VERSION ""

NS_ :

BS_:

BU_: Engine Transmission Brakes Instrument DiagTool

VAL_TABLE_ VT_FMI
    0 "Data Valid Above Normal Range"
    1 "Data Valid Below Normal Range"
    2 "Data Erratic"
    3 "Voltage Above Normal"
    4 "Voltage Below Normal"
    5 "Current Below Normal / Open Circuit"
    6 "Current Above Normal / Ground Fault"
    7 "Mechanical Not Responding"
    8 "Abnormal Frequency"
    9 "Abnormal Update Rate"
    10 "Abnormal Rate of Change"
    11 "Root Cause Unknown"
    12 "Bad Device"
    13 "Out of Calibration"
    14 "Special Instructions"
    15 "Reserved"
    31 "Not Available" ;

VAL_TABLE_ VT_GearStatus
    0 "Neutral"
    126 "Park"
    125 "Reverse"
    251 "Error"
    252 "Not Available" ;

VAL_TABLE_ VT_OnOff
    0 "Off"
    1 "On"
    2 "Error"
    3 "Not Available" ;

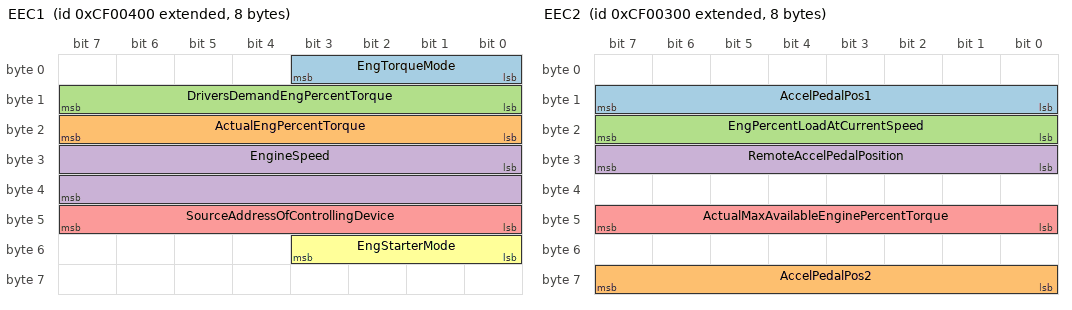
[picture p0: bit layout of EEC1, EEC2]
BO_ 2364539904 EEC1: 8 Engine
 SG_ EngTorqueMode : 0|4@1+ (1,0) [0|15] "" Instrument
 SG_ ActualEngPercentTorque : 16|8@1+ (1,-125) [-125|125] "%" Instrument
 SG_ DriversDemandEngPercentTorque : 8|8@1+ (1,-125) [-125|125] "%" Instrument
 SG_ EngineSpeed : 24|16@1+ (0.125,0) [0|8031.875] "rpm" Instrument,Transmission
 SG_ SourceAddressOfControllingDevice : 40|8@1+ (1,0) [0|255] "" DiagTool
 SG_ EngStarterMode : 48|4@1+ (1,0) [0|15] "" Instrument

BO_ 2364539648 EEC2: 8 Engine
 SG_ AccelPedalPos1 : 8|8@1+ (0.4,0) [0|102] "%" Instrument
 SG_ AccelPedalPos2 : 56|8@1+ (0.4,0) [0|102] "%" Instrument
 SG_ EngPercentLoadAtCurrentSpeed : 16|8@1+ (1,0) [0|100] "%" Instrument
 SG_ RemoteAccelPedalPosition : 24|8@1+ (0.4,0) [0|102] "%" Instrument
 SG_ ActualMaxAvailableEnginePercentTorque : 40|8@1+ (0.4,0) [0|102] "%" Instrument

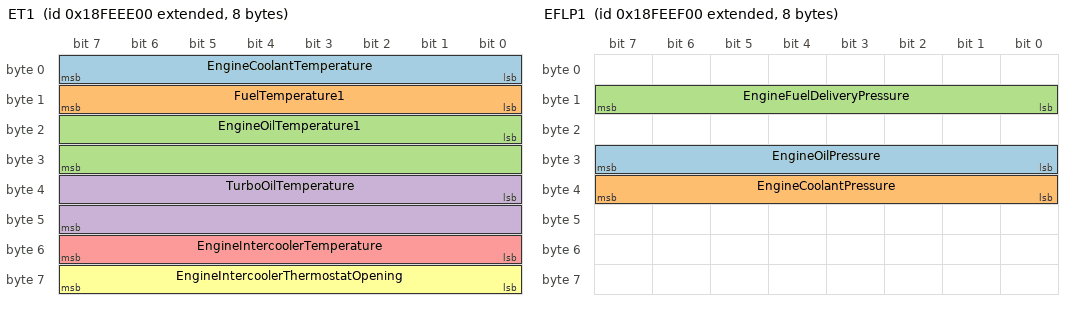
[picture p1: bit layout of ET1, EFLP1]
BO_ 2566843904 ET1: 8 Engine
 SG_ EngineCoolantTemperature : 0|8@1+ (1,-40) [-40|210] "degC" Instrument
 SG_ FuelTemperature1 : 8|8@1+ (1,-40) [-40|210] "degC" Instrument
 SG_ EngineOilTemperature1 : 16|16@1+ (0.03125,-273) [-273|1735] "degC" Instrument
 SG_ TurboOilTemperature : 32|16@1+ (0.03125,-273) [-273|1735] "degC" Instrument
 SG_ EngineIntercoolerTemperature : 48|8@1+ (1,-40) [-40|210] "degC" Instrument
 SG_ EngineIntercoolerThermostatOpening : 56|8@1+ (0.4,0) [0|102] "%" Instrument

BO_ 2566844160 EFLP1: 8 Engine
 SG_ EngineOilPressure : 24|8@1+ (4,0) [0|1000] "kPa" Instrument
 SG_ EngineCoolantPressure : 32|8@1+ (2,0) [0|500] "kPa" Instrument
 SG_ EngineFuelDeliveryPressure : 8|8@1+ (4,0) [0|1000] "kPa" Instrument

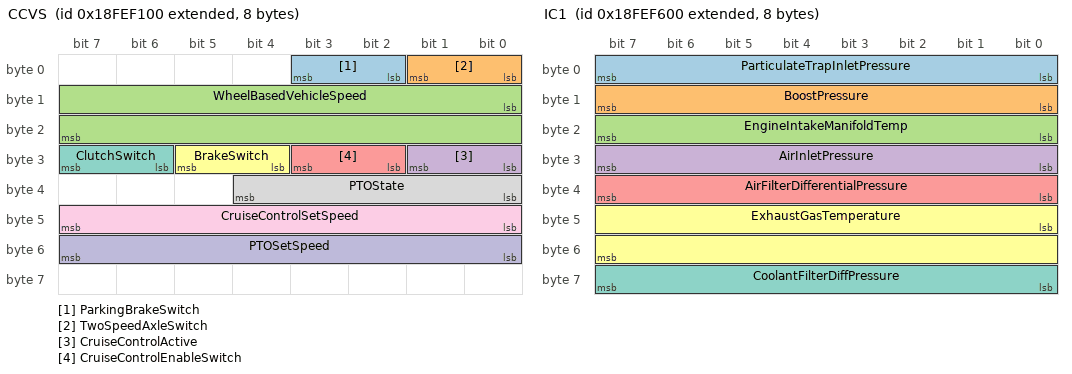
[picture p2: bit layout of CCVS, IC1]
BO_ 2566844672 CCVS: 8 Engine
 SG_ ParkingBrakeSwitch : 2|2@1+ (1,0) [0|3] "" Instrument
 SG_ TwoSpeedAxleSwitch : 0|2@1+ (1,0) [0|3] "" Instrument
 SG_ WheelBasedVehicleSpeed : 8|16@1+ (0.00390625,0) [0|250.996] "km/h" Instrument
 SG_ CruiseControlActive : 24|2@1+ (1,0) [0|3] "" Instrument
 SG_ CruiseControlEnableSwitch : 26|2@1+ (1,0) [0|3] "" Instrument
 SG_ BrakeSwitch : 28|2@1+ (1,0) [0|3] "" Instrument
 SG_ ClutchSwitch : 30|2@1+ (1,0) [0|3] "" Instrument
 SG_ PTOState : 32|5@1+ (1,0) [0|31] "" Instrument
 SG_ CruiseControlSetSpeed : 40|8@1+ (1,0) [0|250] "km/h" Instrument
 SG_ PTOSetSpeed : 48|8@1+ (1,0) [0|255] "rpm" Instrument

BO_ 2566845952 IC1: 8 Engine
 SG_ ParticulateTrapInletPressure : 0|8@1+ (0.5,0) [0|125] "kPa" Instrument
 SG_ BoostPressure : 8|8@1+ (2,0) [0|500] "kPa" Instrument
 SG_ EngineIntakeManifoldTemp : 16|8@1+ (1,-40) [-40|210] "degC" Instrument
 SG_ AirInletPressure : 24|8@1+ (2,0) [0|500] "kPa" Instrument
 SG_ AirFilterDifferentialPressure : 32|8@1+ (0.05,0) [0|12.5] "kPa" Instrument
 SG_ ExhaustGasTemperature : 40|16@1+ (0.03125,-273) [-273|1735] "degC" Instrument
 SG_ CoolantFilterDiffPressure : 56|8@1+ (0.5,0) [0|125] "kPa" Instrument

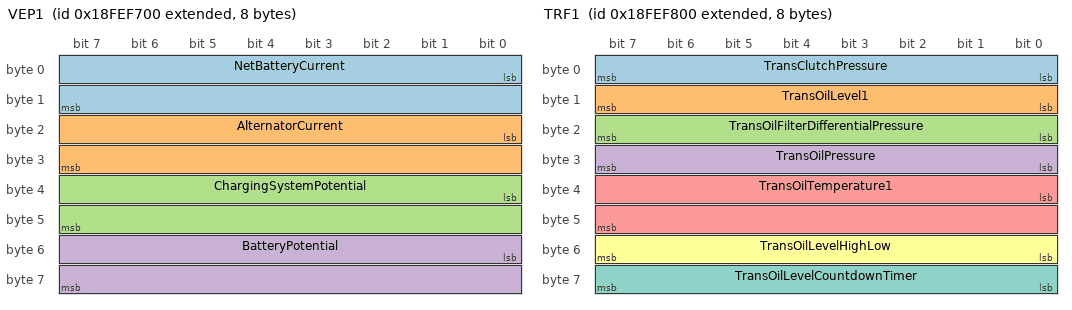
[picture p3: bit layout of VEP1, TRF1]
BO_ 2566846208 VEP1: 8 Engine
 SG_ NetBatteryCurrent : 0|16@1+ (1,-125) [-125|125] "A" Instrument
 SG_ AlternatorCurrent : 16|16@1+ (1,0) [0|250] "A" Instrument
 SG_ ChargingSystemPotential : 32|16@1+ (0.05,0) [0|3212.75] "V" Instrument
 SG_ BatteryPotential : 48|16@1+ (0.05,0) [0|3212.75] "V" Instrument

BO_ 2566846464 TRF1: 8 Transmission
 SG_ TransClutchPressure : 0|8@1+ (16,0) [0|4000] "kPa" Instrument
 SG_ TransOilLevel1 : 8|8@1+ (0.4,0) [0|100] "%" Instrument
 SG_ TransOilFilterDifferentialPressure : 16|8@1+ (2,0) [0|500] "kPa" Instrument
 SG_ TransOilPressure : 24|8@1+ (16,0) [0|4000] "kPa" Instrument
 SG_ TransOilTemperature1 : 32|16@1+ (0.03125,-273) [-273|1735] "degC" Instrument
 SG_ TransOilLevelHighLow : 48|8@1+ (0.4,-50) [-50|51.2] "%" Instrument
 SG_ TransOilLevelCountdownTimer : 56|8@1+ (1,0) [0|250] "s" Instrument

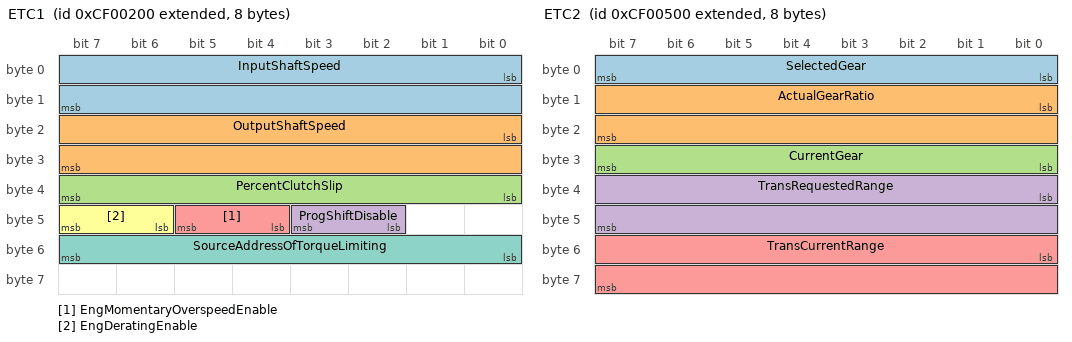
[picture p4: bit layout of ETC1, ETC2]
BO_ 2364539392 ETC1: 8 Transmission
 SG_ InputShaftSpeed : 0|16@1+ (0.125,0) [0|8031.875] "rpm" Instrument
 SG_ OutputShaftSpeed : 16|16@1+ (0.125,0) [0|8031.875] "rpm" Instrument
 SG_ PercentClutchSlip : 32|8@1+ (0.4,0) [0|100] "%" Instrument
 SG_ ProgShiftDisable : 42|2@1+ (1,0) [0|3] "" Instrument
 SG_ EngMomentaryOverspeedEnable : 44|2@1+ (1,0) [0|3] "" Instrument
 SG_ EngDeratingEnable : 46|2@1+ (1,0) [0|3] "" Instrument
 SG_ SourceAddressOfTorqueLimiting : 48|8@1+ (1,0) [0|255] "" DiagTool

BO_ 2364540160 ETC2: 8 Transmission
 SG_ SelectedGear : 0|8@1+ (1,-125) [-125|125] "" Instrument
 SG_ ActualGearRatio : 8|16@1+ (0.001,0) [0|64.255] "" Instrument
 SG_ CurrentGear : 24|8@1+ (1,-125) [-125|125] "" Instrument
 SG_ TransRequestedRange : 32|16@1+ (1,0) [0|65535] "" Transmission
 SG_ TransCurrentRange : 48|16@1+ (1,0) [0|65535] "" Instrument

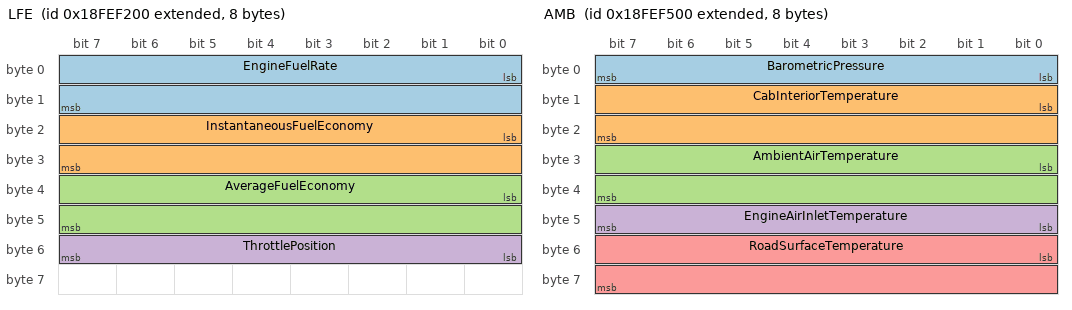
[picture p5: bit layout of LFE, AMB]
BO_ 2566844928 LFE: 8 Engine
 SG_ EngineFuelRate : 0|16@1+ (0.05,0) [0|3212.75] "L/h" Instrument
 SG_ InstantaneousFuelEconomy : 16|16@1+ (0.001953125,0) [0|125.5] "km/L" Instrument
 SG_ AverageFuelEconomy : 32|16@1+ (0.001953125,0) [0|125.5] "km/L" Instrument
 SG_ ThrottlePosition : 48|8@1+ (0.4,0) [0|100] "%" Instrument

BO_ 2566845696 AMB: 8 Engine
 SG_ BarometricPressure : 0|8@1+ (0.5,0) [0|125] "kPa" Instrument
 SG_ CabInteriorTemperature : 8|16@1+ (0.03125,-273) [-273|1735] "degC" Instrument
 SG_ AmbientAirTemperature : 24|16@1+ (0.03125,-273) [-273|1735] "degC" Instrument
 SG_ EngineAirInletTemperature : 40|8@1+ (1,-40) [-40|210] "degC" Instrument
 SG_ RoadSurfaceTemperature : 48|16@1+ (0.03125,-273) [-273|1735] "degC" Instrument

BO_ 2566841600 HOURS: 8 Engine
 SG_ EngTotalHoursOfOperation : 0|32@1+ (0.05,0) [0|214748364.75] "h" Instrument
 SG_ EngTotalRevolutions : 32|32@1+ (1000,0) [0|4294967295000] "r" Instrument

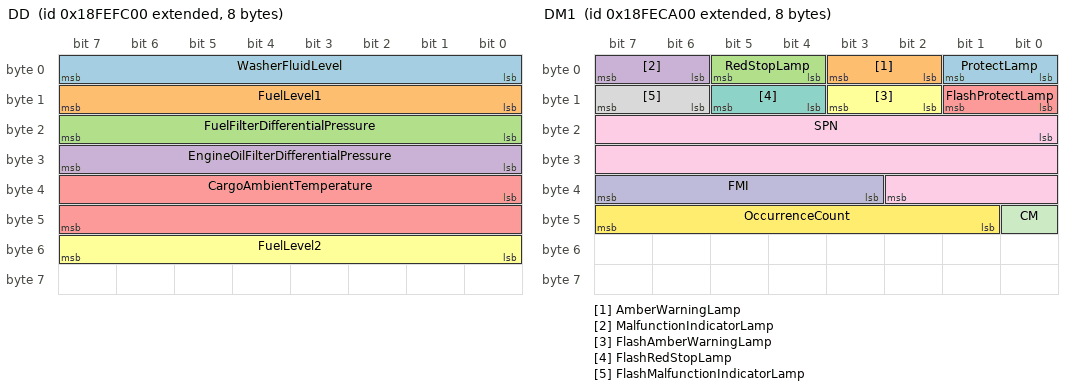
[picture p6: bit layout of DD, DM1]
BO_ 2566847488 DD: 8 Engine
 SG_ WasherFluidLevel : 0|8@1+ (0.4,0) [0|100] "%" Instrument
 SG_ FuelLevel1 : 8|8@1+ (0.4,0) [0|100] "%" Instrument
 SG_ FuelFilterDifferentialPressure : 16|8@1+ (2,0) [0|500] "kPa" Instrument
 SG_ EngineOilFilterDifferentialPressure : 24|8@1+ (0.5,0) [0|125] "kPa" Instrument
 SG_ CargoAmbientTemperature : 32|16@1+ (0.03125,-273) [-273|1735] "degC" Instrument
 SG_ FuelLevel2 : 48|8@1+ (0.4,0) [0|100] "%" Instrument

BO_ 2566832384 VD: 8 Engine
 SG_ TotalVehicleDistance : 0|32@1+ (0.125,0) [0|536870911.875] "km" Instrument
 SG_ TripDistance : 32|32@1+ (0.125,0) [0|536870911.875] "km" Instrument

BO_ 2566834688 DM1: 8 Engine
 SG_ ProtectLamp : 0|2@1+ (1,0) [0|3] "" Instrument
 SG_ AmberWarningLamp : 2|2@1+ (1,0) [0|3] "" Instrument
 SG_ RedStopLamp : 4|2@1+ (1,0) [0|3] "" Instrument
 SG_ MalfunctionIndicatorLamp : 6|2@1+ (1,0) [0|3] "" Instrument
 SG_ FlashProtectLamp : 8|2@1+ (1,0) [0|3] "" Instrument
 SG_ FlashAmberWarningLamp : 10|2@1+ (1,0) [0|3] "" Instrument
 SG_ FlashRedStopLamp : 12|2@1+ (1,0) [0|3] "" Instrument
 SG_ FlashMalfunctionIndicatorLamp : 14|2@1+ (1,0) [0|3] "" Instrument
 SG_ SPN : 16|19@1+ (1,0) [0|524287] "" DiagTool
 SG_ FMI : 35|5@1+ (1,0) [0|31] "" DiagTool
 SG_ CM : 40|1@1+ (1,0) [0|1] "" DiagTool
 SG_ OccurrenceCount : 41|7@1+ (1,0) [0|127] "" DiagTool

BO_ 2565472256 REQUEST: 3 DiagTool
 SG_ PGNRequested : 0|24@1+ (1,0) [0|16777215] "" Engine,Transmission,Brakes

CM_ BU_ Engine "Engine Controller (ECU)";
CM_ BU_ Transmission "Transmission Controller (TCU)";
CM_ BU_ Brakes "Brake Controller (ABS)";
CM_ BU_ Instrument "Instrument Cluster";
CM_ BU_ DiagTool "Off-board Diagnostic Tool";

CM_ BO_ 2364539904 "Electronic Engine Controller 1 - Primary engine control parameters";
CM_ BO_ 2364539648 "Electronic Engine Controller 2 - Secondary engine control parameters";
CM_ BO_ 2566843904 "Engine Temperature 1 - Engine temperature readings";
CM_ BO_ 2566844160 "Engine Fluid Level/Pressure 1 - Oil/coolant/fuel pressures";
CM_ BO_ 2566844672 "Cruise Control/Vehicle Speed - Speed and cruise control status";
CM_ BO_ 2566845952 "Inlet/Exhaust Conditions 1 - Turbo and intake parameters";
CM_ BO_ 2566846208 "Vehicle Electrical Power 1 - Battery and charging info";
CM_ BO_ 2566846464 "Transmission Fluids 1 - Transmission oil parameters";
CM_ BO_ 2364539392 "Electronic Transmission Controller 1 - Shaft speeds and clutch";
CM_ BO_ 2364540160 "Electronic Transmission Controller 2 - Gear selection";
CM_ BO_ 2566844928 "Liquid Fuel Economy - Fuel consumption rates";
CM_ BO_ 2566845696 "Ambient Conditions - Environmental temperatures/pressures";
CM_ BO_ 2566841600 "Engine Hours, Revolutions - Engine total runtime";
CM_ BO_ 2566847488 "Dash Display - Fuel level and filter status";
CM_ BO_ 2566832384 "Vehicle Distance - Odometer and trip distance";
CM_ BO_ 2566834688 "DM1 Active Diagnostic Trouble Codes";
CM_ BO_ 2565472256 "PGN Request Message";

CM_ SG_ 2364539904 EngineSpeed "Engine crankshaft speed - 0.125 RPM/bit";
CM_ SG_ 2364539904 ActualEngPercentTorque "Current engine torque as percentage of reference torque";
CM_ SG_ 2566843904 EngineCoolantTemperature "Temperature of engine coolant fluid";
CM_ SG_ 2566845952 BoostPressure "Turbocharger boost pressure";
CM_ SG_ 2566844672 WheelBasedVehicleSpeed "Vehicle speed from wheel speed sensors";
CM_ SG_ 2364540160 CurrentGear "Currently engaged transmission gear";
CM_ SG_ 2566847488 FuelLevel1 "Primary fuel tank level percentage";

BA_DEF_ BO_  "GenMsgCycleTime" INT 0 10000;
BA_DEF_  "BusType" STRING ;

BA_DEF_DEF_  "GenMsgCycleTime" 0;
BA_DEF_DEF_  "BusType" "";

BA_ "BusType" "CAN";

BA_ "GenMsgCycleTime" BO_ 2364539904 10;
BA_ "GenMsgCycleTime" BO_ 2364539648 50;
BA_ "GenMsgCycleTime" BO_ 2566843904 1000;
BA_ "GenMsgCycleTime" BO_ 2566844160 500;
BA_ "GenMsgCycleTime" BO_ 2566844672 100;
BA_ "GenMsgCycleTime" BO_ 2566845952 500;
BA_ "GenMsgCycleTime" BO_ 2566846208 1000;
BA_ "GenMsgCycleTime" BO_ 2566846464 1000;
BA_ "GenMsgCycleTime" BO_ 2364539392 10;
BA_ "GenMsgCycleTime" BO_ 2364540160 100;
BA_ "GenMsgCycleTime" BO_ 2566844928 100;
BA_ "GenMsgCycleTime" BO_ 2566845696 1000;
BA_ "GenMsgCycleTime" BO_ 2566841600 1000;
BA_ "GenMsgCycleTime" BO_ 2566847488 1000;
BA_ "GenMsgCycleTime" BO_ 2566832384 1000;

    0 "Low Idle Governor/No Request"
    1 "Accelerator Pedal/Operator Selection"
    2 "Cruise Control"
    3 "PTO Governor"
    4 "Road Speed Governor"
    5 "ASR Control"
    6 "Transmission Control"
    7 "ABS Control"
    8 "Torque Limiting"
    9 "High Speed Governor"
    10 "Braking System"
    11 "Remote Accelerator"
    14 "Other"
    15 "Not Available" ;

    0 "Start not requested"
    1 "Starter Active, Gear not engaged"
    2 "Starter Active, Gear engaged"
    3 "Start Finished"
    4 "Starter Inhibited due to engine already running"
    5 "Starter Inhibited due to engine not ready"
    6 "Starter Inhibited due to driveline engaged"
    12 "Starter Inhibited - reason unknown"
    13 "Error"
    14 "Reserved"
    15 "Not Available" ;

    0 "Parking brake not set"
    1 "Parking brake set"
    2 "Error"
    3 "Not available" ;

    0 "Brake pedal released"
    1 "Brake pedal depressed"
    2 "Error"
    3 "Not available" ;

    0 "Clutch pedal released"
    1 "Clutch pedal depressed"
    2 "Error"
    3 "Not available" ;

    0 "Cruise control switched off"
    1 "Cruise control switched on"
    2 "Error"
    3 "Not available" ;

VAL_ 2566834688 ProtectLamp 0 "Off" 1 "On" 2 "Error" 3 "Not available" ;
VAL_ 2566834688 AmberWarningLamp 0 "Off" 1 "On" 2 "Error" 3 "Not available" ;
VAL_ 2566834688 RedStopLamp 0 "Off" 1 "On" 2 "Error" 3 "Not available" ;
VAL_ 2566834688 MalfunctionIndicatorLamp 0 "Off" 1 "On" 2 "Error" 3 "Not available" ;
VAL_ 2566834688 FlashProtectLamp 0 "Slow Flash" 1 "Fast Flash" 2 "Error" 3 "Not available" ;
VAL_ 2566834688 FlashAmberWarningLamp 0 "Slow Flash" 1 "Fast Flash" 2 "Error" 3 "Not available" ;
VAL_ 2566834688 FlashRedStopLamp 0 "Slow Flash" 1 "Fast Flash" 2 "Error" 3 "Not available" ;
VAL_ 2566834688 FlashMalfunctionIndicatorLamp 0 "Slow Flash" 1 "Fast Flash" 2 "Error" 3 "Not available" ;
